# nrf9160_modem register map
Vendor: Nordic Semiconductor; Series: nrf91; File version: 1
CPU: CM4 r0p1, little endian, MPU, FPU, 3 interrupt priority bits
Registers are 32-bit, read-write, reset 0x0 unless marked. A register's access mark holds for its fields unless they carry their own. Offsets are from the block's base; [hi:lo] are bit positions; lines under a group give offsets from that group; 'fields as' and 'values as' point back to an identical list.

## RAMBISTHUB_NS — RAM BIST Hub
Base 0x4002B000
0x00 RUN — RUN BIST
  [0] RUN
    0=Clear the task; 1=Set (Run the task)
0x100 SLEEP — BIST SLEEP EVENT
  [0] SLEEP
    0=No event detected. Write zero to clear the event.; 1=EventDetected
0x104 FINISHED — BIST FINISHED EVENT
  [0] FINISHED
    values as SLEEP.SLEEP
0x500 HUBENABLE — RAM BIST Hub enable
  [0] HUBENABLE
    0=Disabled (RAM BIST Hub disabled); 1=Enabled (RAM BIST Hub enabled)
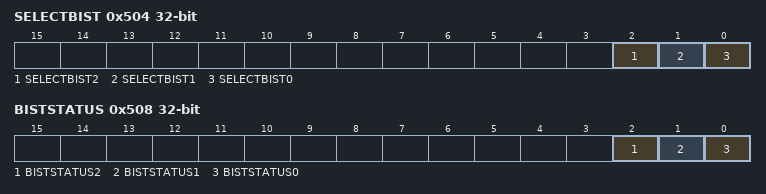
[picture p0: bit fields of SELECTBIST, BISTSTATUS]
0x504 SELECTBIST — Select bits for the individual BISTs to run
  [2] SELECTBIST2 — Select and enable BIST2
    0=Disabled (BIST2 disabled); 1=Enabled (BIST2 enabled)
  [1] SELECTBIST1 — Select and enable BIST1
    0=Disabled (BIST1 disabled); 1=Enabled (BIST1 enabled)
  [0] SELECTBIST0 — Select and enable BIST0
    0=Disabled (BIST0 disabled); 1=Enabled (BIST0 enabled)
0x508 BISTSTATUS
  [2] BISTSTATUS2 — Status of BIST2. Write to clear.
    0=NotPassed (Read: BIST2 not passed); 1=Passed (Read: BIST2 passed. Write zero to clear.)
  [1] BISTSTATUS1 — Status of BIST1. Write to clear.
    0=NotPassed (Read: BIST1 not passed); 1=Passed (Read: BIST1 passed. Write zero to clear.)
  [0] BISTSTATUS0 — Status of BIST0. Write to clear.
    0=NotPassed (Read: BIST0 not passed); 1=Passed (Read: BIST0 passed. Write zero to clear.)
0x50C TESTTYPE — RAM BIST test type
  [0] TESTTYPE — RAM BIST Hub enable
    0=BIST (Non-retention BIST); 1=RetentionBIST
0x510 FORCEONRETENTION wo — Power request override to force RAM retention on
  [0] FORCEONRETENTION
    0=Disabled (Power request override disabled); 1=Enabled (Power request override enabled)

## M2M0_NS — Memory to Memory DMA 0
Base 0x4002E000
Same registers: M2M1_NS 0x4002F000
0x00 TASKS_START wo — Start DMA transfer
  [0] TASKS_START
    1=Trigger task
0x04 TASKS_STOP wo — Stop DMA transfer
  [0] TASKS_STOP
    1=Trigger task
0x100 EVENTS_END — DMA transfer complete
  [0] EVENTS_END
    0=NotGenerated (Event not generated); 1=Generated (Event generated)
0x104 EVENTS_STARTED — DMA transfer started
  [0] EVENTS_STARTED
    values as EVENTS_END.EVENTS_END
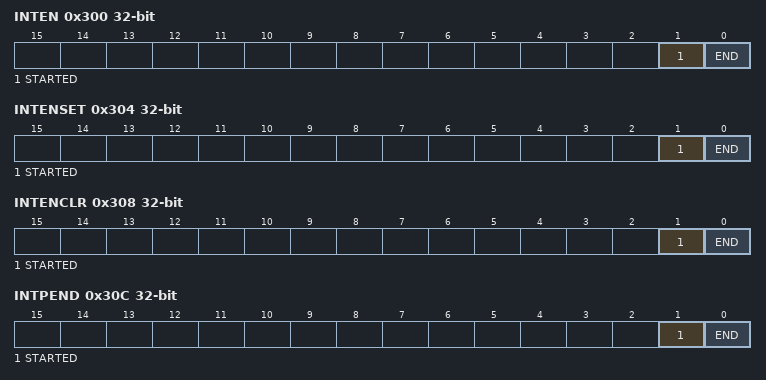
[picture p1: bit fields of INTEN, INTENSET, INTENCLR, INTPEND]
0x300 INTEN — Enable or disable interrupt
  [1] STARTED — Enable or disable interrupt for event STARTED
    0=Disabled; 1=Enabled
  [0] END — Enable or disable interrupt for event END
    0=Disabled; 1=Enabled
0x304 INTENSET — Enable interrupt
  [1] STARTED — Write '1' to enable interrupt for event STARTED
    on read: 0=Disabled (Read: Disabled); 1=Enabled (Read: Enabled) | on write: 1=Set (Enable)
  [0] END — Write '1' to enable interrupt for event END
    values as STARTED
0x308 INTENCLR — Disable interrupt
  [1] STARTED — Write '1' to disable interrupt for event STARTED
    on read: 0=Disabled (Read: Disabled); 1=Enabled (Read: Enabled) | on write: 1=Clear (Disable)
  [0] END — Write '1' to disable interrupt for event END
    values as STARTED
0x30C INTPEND ro — Pending interrupts
  [1] STARTED — Read pending status of interrupt for event STARTED
    on read: 0=NotPending (Read: Not pending); 1=Pending (Read: Pending)
  [0] END — Read pending status of interrupt for event END
    values as STARTED
0x510 IN group — Memory to memory input channel
  0x00 PTR — Data pointer
  0x04 MAXCNT — Maximum number of bytes in input and output buffer
    [7:0] MAXCNT
  0x08 AMOUNT ro — Number of bytes transferred in the last transaction
    [7:0] AMOUNT
  0x0C LIST — EasyDMA list type
    [2:0] LIST — List type
      0=Disabled (Disable EasyDMA list); 1=ArrayList (Use array list)
0x520 OUT group — Memory to memory output channel
  0x00 PTR — Data pointer
  0x04 AMOUNT ro — Number of bytes transferred in the last transaction
    [7:0] AMOUNT
  0x08 LIST — EasyDMA list type
    fields as IN.LIST
